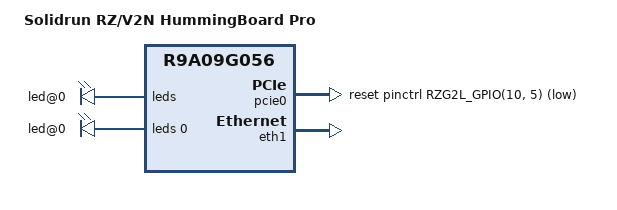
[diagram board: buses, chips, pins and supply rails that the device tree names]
// SPDX-License-Identifier: (GPL-2.0-only OR BSD-2-Clause)
/*
 * Device Tree Source for the RZ/V2N SolidRun HummingBoard Pro
 *
 * Copyright (C) 2025 SolidRun Ltd.
 */

/dts-v1/;

#include "rzv2n-sr-som.dtsi"
#include "rzv2n-hummingboard-puls.dtsi"

/ {
	model = "Solidrun RZ/V2N HummingBoard Pro";
	compatible = "renesas,rzv2n-sr-som", "renesas,r9a09g056n44", "renesas,r9a09g056";
};

&pcie0 {
	reset-gpios = <&pinctrl RZG2L_GPIO(10, 5) GPIO_ACTIVE_LOW>; /* PA5 */
	status = "okay";
};

&eth1 {
	status = "okay";
};

&phy0 {
	leds {
		led@0 {
			/* colour is changed from HB Pulse to Pro. */
			color = <LED_COLOR_ID_GREEN>;
		};

		/* HB Pro has single led only. */
		/delete-node/ led@1;
	};
};

&phy1 {
	leds {
		#address-cells = <1>;
		#size-cells = <0>;

		/* MxL86110 LED0 pin */
		led@0 {
			reg = <0>;
			color = <LED_COLOR_ID_GREEN>;
			function = LED_FUNCTION_LAN;
			default-state = "keep";
		};
	};
};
